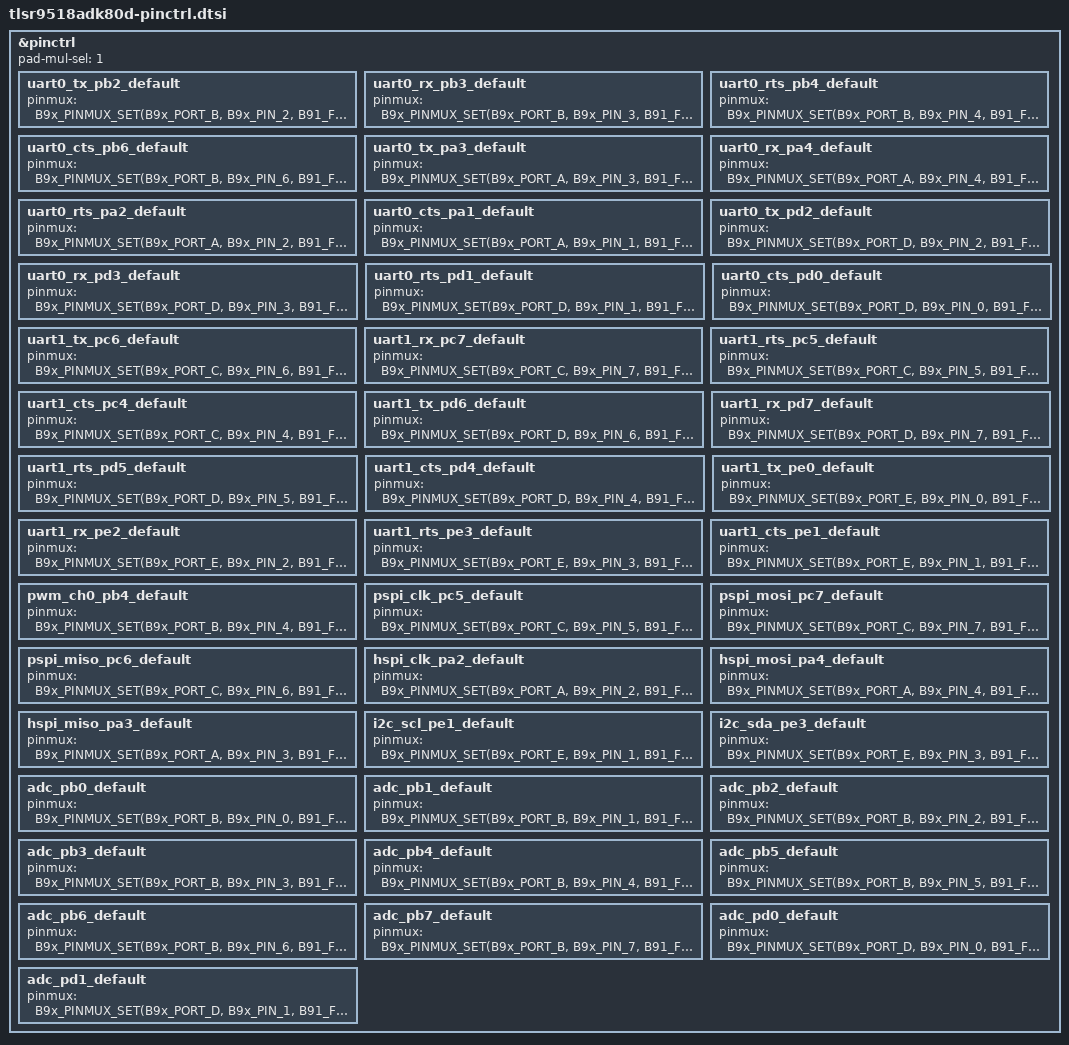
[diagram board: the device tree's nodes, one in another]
/*
 * Copyright (c) 2022-2024 Telink Semiconductor
 *
 * SPDX-License-Identifier: Apache-2.0
 */

#include <zephyr/dt-bindings/pinctrl/b91-pinctrl.h>

&pinctrl {
	/* Set pad-mul-sel register value.
	 * Note: Pins functions below (pinmux = <...>) depend on this value.
	 */
	pad-mul-sel = <1>;

	/* UART0: TX(PB2), RX(PB3), RTS(PB4), CTS(PB6) */

	uart0_tx_pb2_default: uart0_tx_pb2_default {
		pinmux = <B9x_PINMUX_SET(B9x_PORT_B, B9x_PIN_2, B91_FUNC_C)>;
	};
	uart0_rx_pb3_default: uart0_rx_pb3_default {
		pinmux = <B9x_PINMUX_SET(B9x_PORT_B, B9x_PIN_3, B91_FUNC_C)>;
	};
	uart0_rts_pb4_default: uart0_rts_pb4_default {
		pinmux = <B9x_PINMUX_SET(B9x_PORT_B, B9x_PIN_4, B91_FUNC_C)>;
	};
	uart0_cts_pb6_default: uart0_cts_pb6_default {
		pinmux = <B9x_PINMUX_SET(B9x_PORT_B, B9x_PIN_6, B91_FUNC_C)>;
	};

	/* UART0: TX(PA3), RX(PA4), RTS(PA2), CTS(PA1) */

	uart0_tx_pa3_default: uart0_tx_pa3_default {
		pinmux = <B9x_PINMUX_SET(B9x_PORT_A, B9x_PIN_3, B91_FUNC_B)>;
	};
	uart0_rx_pa4_default: uart0_rx_pa4_default {
		pinmux = <B9x_PINMUX_SET(B9x_PORT_A, B9x_PIN_4, B91_FUNC_B)>;
	};
	uart0_rts_pa2_default: uart0_rts_pa2_default {
		pinmux = <B9x_PINMUX_SET(B9x_PORT_A, B9x_PIN_2, B91_FUNC_B)>;
	};
	uart0_cts_pa1_default: uart0_cts_pa1_default {
		pinmux = <B9x_PINMUX_SET(B9x_PORT_A, B9x_PIN_1, B91_FUNC_B)>;
	};

	/* UART0: TX(PD2), RX(PD3), RTS(PD1), CTS(PD0) */

	uart0_tx_pd2_default: uart0_tx_pd2_default {
		pinmux = <B9x_PINMUX_SET(B9x_PORT_D, B9x_PIN_2, B91_FUNC_A)>;
	};
	uart0_rx_pd3_default: uart0_rx_pd3_default {
		pinmux = <B9x_PINMUX_SET(B9x_PORT_D, B9x_PIN_3, B91_FUNC_A)>;
	};
	uart0_rts_pd1_default: uart0_rts_pd1_default {
		pinmux = <B9x_PINMUX_SET(B9x_PORT_D, B9x_PIN_1, B91_FUNC_A)>;
	};
	uart0_cts_pd0_default: uart0_cts_pd0_default {
		pinmux = <B9x_PINMUX_SET(B9x_PORT_D, B9x_PIN_0, B91_FUNC_A)>;
	};

	/* UART1: TX(PC6), RX(PC7), RTS(PC5), CTS(PC4) */

	uart1_tx_pc6_default: uart1_tx_pc6_default {
		pinmux = <B9x_PINMUX_SET(B9x_PORT_C, B9x_PIN_6, B91_FUNC_C)>;
	};
	uart1_rx_pc7_default: uart1_rx_pc7_default {
		pinmux = <B9x_PINMUX_SET(B9x_PORT_C, B9x_PIN_7, B91_FUNC_C)>;
	};
	uart1_rts_pc5_default: uart1_rts_pc5_default {
		pinmux = <B9x_PINMUX_SET(B9x_PORT_C, B9x_PIN_5, B91_FUNC_C)>;
	};
	uart1_cts_pc4_default: uart1_cts_pc4_default {
		pinmux = <B9x_PINMUX_SET(B9x_PORT_C, B9x_PIN_4, B91_FUNC_C)>;
	};

	/* UART1: TX(PD6), RX(PD7), RTS(PD5), CTS(PD4) */

	uart1_tx_pd6_default: uart1_tx_pd6_default {
		pinmux = <B9x_PINMUX_SET(B9x_PORT_D, B9x_PIN_6, B91_FUNC_A)>;
	};
	uart1_rx_pd7_default: uart1_rx_pd7_default {
		pinmux = <B9x_PINMUX_SET(B9x_PORT_D, B9x_PIN_7, B91_FUNC_A)>;
	};
	uart1_rts_pd5_default: uart1_rts_pd5_default {
		pinmux = <B9x_PINMUX_SET(B9x_PORT_D, B9x_PIN_5, B91_FUNC_A)>;
	};
	uart1_cts_pd4_default: uart1_cts_pd4_default {
		pinmux = <B9x_PINMUX_SET(B9x_PORT_D, B9x_PIN_4, B91_FUNC_A)>;
	};

	/* UART1: TX(PE0), RX(PE2), RTS(PE3), CTS(PE1) */

	uart1_tx_pe0_default: uart1_tx_pe0_default {
		pinmux = <B9x_PINMUX_SET(B9x_PORT_E, B9x_PIN_0, B91_FUNC_B)>;
	};
	uart1_rx_pe2_default: uart1_rx_pe2_default {
		pinmux = <B9x_PINMUX_SET(B9x_PORT_E, B9x_PIN_2, B91_FUNC_B)>;
	};
	uart1_rts_pe3_default: uart1_rts_pe3_default {
		pinmux = <B9x_PINMUX_SET(B9x_PORT_E, B9x_PIN_3, B91_FUNC_B)>;
	};
	uart1_cts_pe1_default: uart1_cts_pe1_default {
		pinmux = <B9x_PINMUX_SET(B9x_PORT_E, B9x_PIN_1, B91_FUNC_B)>;
	};

	/* PWM Channel 0 (PB4) */

	pwm_ch0_pb4_default: pwm_ch0_pb4_default {
		pinmux = <B9x_PINMUX_SET(B9x_PORT_B, B9x_PIN_4, B91_FUNC_B)>;
	};

	/* PSPI: CLK(PC5), MOSI(PC7), MISO(PC6) */

	pspi_clk_pc5_default: pspi_clk_pc5_default {
		pinmux = <B9x_PINMUX_SET(B9x_PORT_C, B9x_PIN_5, B91_FUNC_A)>;
	};
	pspi_mosi_pc7_default: pspi_mosi_pc7_default {
		pinmux = <B9x_PINMUX_SET(B9x_PORT_C, B9x_PIN_7, B91_FUNC_A)>;
	};
	pspi_miso_pc6_default: pspi_miso_pc6_default {
		pinmux = <B9x_PINMUX_SET(B9x_PORT_C, B9x_PIN_6, B91_FUNC_A)>;
	};

	/* HSPI: CLK(PA2), MOSI(PA4), MISO(PA3) */

	hspi_clk_pa2_default: hspi_clk_pa2_default {
		pinmux = <B9x_PINMUX_SET(B9x_PORT_A, B9x_PIN_2, B91_FUNC_C)>;
	};
	hspi_mosi_pa4_default: hspi_mosi_pa4_default {
		pinmux = <B9x_PINMUX_SET(B9x_PORT_A, B9x_PIN_4, B91_FUNC_C)>;
	};
	hspi_miso_pa3_default: hspi_miso_pa3_default {
		pinmux = <B9x_PINMUX_SET(B9x_PORT_A, B9x_PIN_3, B91_FUNC_C)>;
	};

	/* Define I2C pins: SCL(PE1), SDA(PE3) */

	i2c_scl_pe1_default: i2c_scl_pe1_default {
		pinmux = <B9x_PINMUX_SET(B9x_PORT_E, B9x_PIN_1, B91_FUNC_A)>;
	};
	i2c_sda_pe3_default: i2c_sda_pe3_default {
		pinmux = <B9x_PINMUX_SET(B9x_PORT_E, B9x_PIN_3, B91_FUNC_A)>;
	};

	/* Define ADC pins: PB0..PB7, PD0-PD1 */

	adc_pb0_default: adc_pb0_default {
		pinmux = <B9x_PINMUX_SET(B9x_PORT_B, B9x_PIN_0, B91_FUNC_A)>;
	};
	adc_pb1_default: adc_pb1_default {
		pinmux = <B9x_PINMUX_SET(B9x_PORT_B, B9x_PIN_1, B91_FUNC_A)>;
	};
	adc_pb2_default: adc_pb2_default {
		pinmux = <B9x_PINMUX_SET(B9x_PORT_B, B9x_PIN_2, B91_FUNC_A)>;
	};
	adc_pb3_default: adc_pb3_default {
		pinmux = <B9x_PINMUX_SET(B9x_PORT_B, B9x_PIN_3, B91_FUNC_A)>;
	};
	adc_pb4_default: adc_pb4_default {
		pinmux = <B9x_PINMUX_SET(B9x_PORT_B, B9x_PIN_4, B91_FUNC_A)>;
	};
	adc_pb5_default: adc_pb5_default {
		pinmux = <B9x_PINMUX_SET(B9x_PORT_B, B9x_PIN_5, B91_FUNC_A)>;
	};
	adc_pb6_default: adc_pb6_default {
		pinmux = <B9x_PINMUX_SET(B9x_PORT_B, B9x_PIN_6, B91_FUNC_A)>;
	};
	adc_pb7_default: adc_pb7_default {
		pinmux = <B9x_PINMUX_SET(B9x_PORT_B, B9x_PIN_7, B91_FUNC_A)>;
	};
	adc_pd0_default: adc_pd0_default {
		pinmux = <B9x_PINMUX_SET(B9x_PORT_D, B9x_PIN_0, B91_FUNC_A)>;
	};
	adc_pd1_default: adc_pd1_default {
		pinmux = <B9x_PINMUX_SET(B9x_PORT_D, B9x_PIN_1, B91_FUNC_A)>;
	};
};
